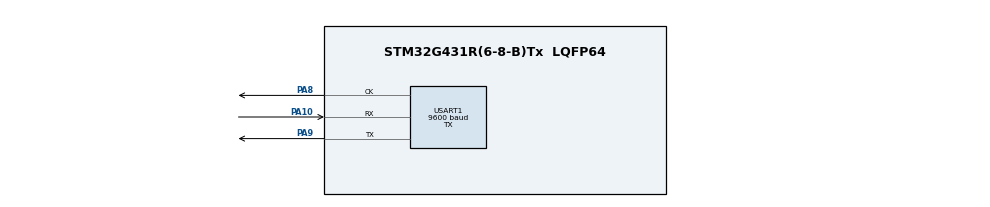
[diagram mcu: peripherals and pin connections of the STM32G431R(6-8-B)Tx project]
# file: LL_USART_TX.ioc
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Mcu.Family=STM32G4
Mcu.Name=STM32G431R(6-8-B)Tx
Mcu.Package=LQFP64
NVIC.PriorityGroup=NVIC_PRIORITYGROUP_4
PA10.Mode=Synchronous
PA10.Signal=USART1_RX
PA8.Mode=Synchronous
PA8.Signal=USART1_CK
PA9.Mode=Synchronous
PA9.Signal=USART1_TX
PF0-OSC_IN.Mode=HSE-External-Oscillator
PF0-OSC_IN.Signal=RCC_OSC_IN
PF1-OSC_OUT.Mode=HSE-External-Oscillator
PF1-OSC_OUT.Signal=RCC_OSC_OUT
ProjectManager.HeapSize=0x200
ProjectManager.StackSize=0x400
ProjectManager.TargetToolchain=MDK-ARM V5.27
RCC.ADC12Freq_Value=80000000
RCC.AHBFreq_Value=80000000
RCC.APB1Freq_Value=80000000
RCC.APB1TimFreq_Value=80000000
RCC.APB2Freq_Value=80000000
RCC.APB2TimFreq_Value=80000000
RCC.CortexFreq_Value=80000000
RCC.EXTERNAL_CLOCK_VALUE=12288000
RCC.HCLKFreq_Value=80000000
RCC.HSE_VALUE=24000000
RCC.HSI48_VALUE=48000000
RCC.HSI_VALUE=16000000
RCC.LSE_VALUE=32768
RCC.PLLM=RCC_PLLM_DIV2
RCC.PLLN=20
RCC.SYSCLKFreq_VALUE=80000000
RCC.SYSCLKSource=RCC_SYSCLKSOURCE_PLLCLK
RCC.USBFreq_Value=80000000
RCC.VCOOutputFreq_Value=160000000
USART1.BaudRate=9600
USART1.Mode=MODE_TX
USART1.VirtualMode-Synchronous=VM_SYNC
VP_SYS_VS_DBSignals.Mode=DisableDeadBatterySignals
board=custom

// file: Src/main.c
/* USER CODE BEGIN Header */
/**
  ******************************************************************************
  * @file           : main.c
  * @brief          : Main program body
  ******************************************************************************
  * @attention
  *
  * <h2><center>&copy; Copyright (c) 2020 STMicroelectronics.
  * All rights reserved.</center></h2>
  *
  * This software component is licensed by ST under BSD 3-Clause license,
  * the "License"; You may not use this file except in compliance with the
  * License. You may obtain a copy of the License at:
  *                        opensource.org/licenses/BSD-3-Clause
  *
  ******************************************************************************
  */
/* USER CODE END Header */

#include "main.h"
#include "stdio.h"
#include "string.h"

void SystemClock_Config(void);
static void MX_GPIO_Init(void);
static void MX_USART1_Init(void);

int main(void)
{
  /* USER CODE BEGIN 1 */
	int counter = 0;
	char str[40];
	int index = 0;

  /* USER CODE END 1 */

  /* MCU Configuration--------------------------------------------------------*/

  /* Reset of all peripherals, Initializes the Flash interface and the Systick. */

  LL_APB2_GRP1_EnableClock(LL_APB2_GRP1_PERIPH_SYSCFG);
  LL_APB1_GRP1_EnableClock(LL_APB1_GRP1_PERIPH_PWR);

  NVIC_SetPriorityGrouping(NVIC_PRIORITYGROUP_4);

  /* System interrupt init*/

  /** Disable the internal Pull-Up in Dead Battery pins of UCPD peripheral
  */
  LL_PWR_DisableDeadBatteryPD();

  /* Configure the system clock */
  SystemClock_Config();

  /* Initialize all configured peripherals */
  MX_GPIO_Init();
  MX_USART1_Init();

  /* Infinite loop */
  /* USER CODE BEGIN WHILE */
  while (1)
  {
		sprintf(str, "%04d:Hello,world.\r\n", counter);

		for(index=0; index< strlen(str); index++){
			LL_USART_TransmitData8(USART1, *(str + index));
			while(!LL_USART_IsActiveFlag_TC(USART1));
		}

		LL_mDelay(500);

		if(++counter == 10000){
			counter = 0;
		}

  }
  /* USER CODE END 3 */
}

void SystemClock_Config(void)
{
  LL_FLASH_SetLatency(LL_FLASH_LATENCY_3);

   if(LL_FLASH_GetLatency() != LL_FLASH_LATENCY_3)
  {
    Error_Handler();
  }
  LL_PWR_SetRegulVoltageScaling(LL_PWR_REGU_VOLTAGE_SCALE1);
  LL_RCC_HSI_Enable();

   /* Wait till HSI is ready */
  while(LL_RCC_HSI_IsReady() != 1)
  {

  }
  LL_RCC_HSI_SetCalibTrimming(64);
  LL_RCC_PLL_ConfigDomain_SYS(LL_RCC_PLLSOURCE_HSI, LL_RCC_PLLM_DIV_2, 20, LL_RCC_PLLR_DIV_2);
  LL_RCC_PLL_EnableDomain_SYS();
  LL_RCC_PLL_Enable();

   /* Wait till PLL is ready */
  while(LL_RCC_PLL_IsReady() != 1)
  {

  }
  LL_RCC_SetSysClkSource(LL_RCC_SYS_CLKSOURCE_PLL);

   /* Wait till System clock is ready */
  while(LL_RCC_GetSysClkSource() != LL_RCC_SYS_CLKSOURCE_STATUS_PLL)
  {

  }
  /* Set AHB prescaler*/
  LL_RCC_SetAHBPrescaler(LL_RCC_SYSCLK_DIV_1);
  LL_RCC_SetAPB1Prescaler(LL_RCC_APB1_DIV_1);
  LL_RCC_SetAPB2Prescaler(LL_RCC_APB1_DIV_1);

  LL_Init1msTick(80000000);

  LL_SetSystemCoreClock(80000000);
  LL_RCC_SetUSARTClockSource(LL_RCC_USART1_CLKSOURCE_PCLK2);
}

static void MX_USART1_Init(void)
{

  LL_USART_InitTypeDef USART_InitStruct = {0};
  LL_USART_ClockInitTypeDef USART_ClockInitStruct = {0};

  LL_GPIO_InitTypeDef GPIO_InitStruct = {0};

  /* Peripheral clock enable */
  LL_APB2_GRP1_EnableClock(LL_APB2_GRP1_PERIPH_USART1);

  LL_AHB2_GRP1_EnableClock(LL_AHB2_GRP1_PERIPH_GPIOA);
  /**USART1 GPIO Configuration
  PA8   ------> USART1_CK
  PA9   ------> USART1_TX
  PA10   ------> USART1_RX
  */
  GPIO_InitStruct.Pin = LL_GPIO_PIN_8;
  GPIO_InitStruct.Mode = LL_GPIO_MODE_ALTERNATE;
  GPIO_InitStruct.Speed = LL_GPIO_SPEED_FREQ_LOW;
  GPIO_InitStruct.OutputType = LL_GPIO_OUTPUT_PUSHPULL;
  GPIO_InitStruct.Pull = LL_GPIO_PULL_NO;
  GPIO_InitStruct.Alternate = LL_GPIO_AF_7;
  LL_GPIO_Init(GPIOA, &GPIO_InitStruct);

  GPIO_InitStruct.Pin = LL_GPIO_PIN_9;
  GPIO_InitStruct.Mode = LL_GPIO_MODE_ALTERNATE;
  GPIO_InitStruct.Speed = LL_GPIO_SPEED_FREQ_LOW;
  GPIO_InitStruct.OutputType = LL_GPIO_OUTPUT_PUSHPULL;
  GPIO_InitStruct.Pull = LL_GPIO_PULL_NO;
  GPIO_InitStruct.Alternate = LL_GPIO_AF_7;
  LL_GPIO_Init(GPIOA, &GPIO_InitStruct);

  GPIO_InitStruct.Pin = LL_GPIO_PIN_10;
  GPIO_InitStruct.Mode = LL_GPIO_MODE_ALTERNATE;
  GPIO_InitStruct.Speed = LL_GPIO_SPEED_FREQ_LOW;
  GPIO_InitStruct.OutputType = LL_GPIO_OUTPUT_PUSHPULL;
  GPIO_InitStruct.Pull = LL_GPIO_PULL_NO;
  GPIO_InitStruct.Alternate = LL_GPIO_AF_7;
  LL_GPIO_Init(GPIOA, &GPIO_InitStruct);

  USART_InitStruct.PrescalerValue = LL_USART_PRESCALER_DIV1;
  USART_InitStruct.BaudRate = 9600;
  USART_InitStruct.DataWidth = LL_USART_DATAWIDTH_8B;
  USART_InitStruct.StopBits = LL_USART_STOPBITS_1;
  USART_InitStruct.Parity = LL_USART_PARITY_NONE;
  USART_InitStruct.TransferDirection = LL_USART_DIRECTION_TX;
  USART_InitStruct.OverSampling = LL_USART_OVERSAMPLING_8;

  LL_USART_Init(USART1, &USART_InitStruct);
  LL_USART_SetTXFIFOThreshold(USART1, LL_USART_FIFOTHRESHOLD_1_8);
  LL_USART_SetRXFIFOThreshold(USART1, LL_USART_FIFOTHRESHOLD_1_8);
  USART_ClockInitStruct.ClockPolarity = LL_USART_POLARITY_LOW;
  USART_ClockInitStruct.ClockPhase = LL_USART_PHASE_1EDGE;
  USART_ClockInitStruct.LastBitClockPulse = LL_USART_LASTCLKPULSE_NO_OUTPUT;
  LL_USART_ClockInit(USART1, &USART_ClockInitStruct);
  LL_USART_DisableFIFO(USART1);
  LL_USART_ConfigSyncMode(USART1);

  LL_USART_Enable(USART1);

  /* Polling USART1 initialisation */
  while(!(LL_USART_IsActiveFlag_TEACK(USART1)))
  {
  }

}

static void MX_GPIO_Init(void)
{

  /* GPIO Ports Clock Enable */
  LL_AHB2_GRP1_EnableClock(LL_AHB2_GRP1_PERIPH_GPIOF);
  LL_AHB2_GRP1_EnableClock(LL_AHB2_GRP1_PERIPH_GPIOA);

}

void Error_Handler(void)
{
}

/************************ (C) COPYRIGHT STMicroelectronics *****END OF FILE****/
